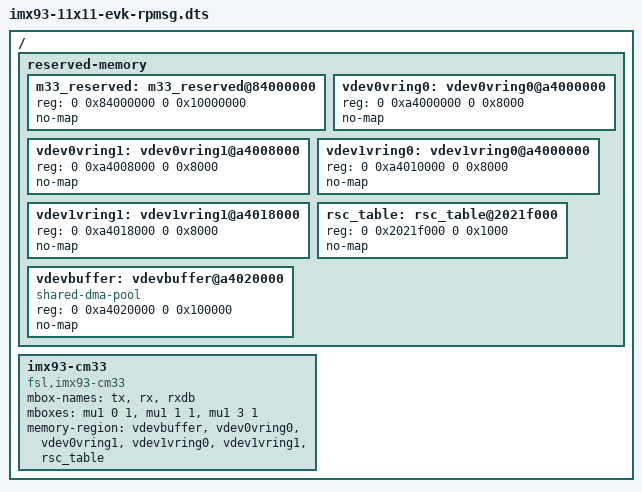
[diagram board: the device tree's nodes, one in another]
// SPDX-License-Identifier: (GPL-2.0+ OR MIT)
/*
 * Copyright 2022 NXP
 */

#include "imx93-11x11-evk.dts"

/{

	reserved-memory {
		#address-cells = <2>;
		#size-cells = <2>;
		ranges;

		m33_reserved: m33_reserved@84000000 {
			reg = <0 0x84000000 0 0x10000000>;
			no-map;
		};

		vdev0vring0: vdev0vring0@a4000000 {
			reg = <0 0xa4000000 0 0x8000>;
			no-map;
		};

		vdev0vring1: vdev0vring1@a4008000 {
			reg = <0 0xa4008000 0 0x8000>;
			no-map;
		};

		vdev1vring0: vdev1vring0@a4000000 {
			reg = <0 0xa4010000 0 0x8000>;
			no-map;
		};

		vdev1vring1: vdev1vring1@a4018000 {
			reg = <0 0xa4018000 0 0x8000>;
			no-map;
		};

		rsc_table: rsc_table@2021f000 {
			reg = <0 0x2021f000 0 0x1000>;
			no-map;
		};

		vdevbuffer: vdevbuffer@a4020000 {
			compatible = "shared-dma-pool";
			reg = <0 0xa4020000 0 0x100000>;
			no-map;
		};
	};

	imx93-cm33 {
		compatible = "fsl,imx93-cm33";
		mbox-names = "tx", "rx", "rxdb";
		mboxes = <&mu1 0 1
			  &mu1 1 1
			  &mu1 3 1>;
		memory-region = <&vdevbuffer>, <&vdev0vring0>, <&vdev0vring1>,
				<&vdev1vring0>, <&vdev1vring1>, <&rsc_table>;
	};
};
